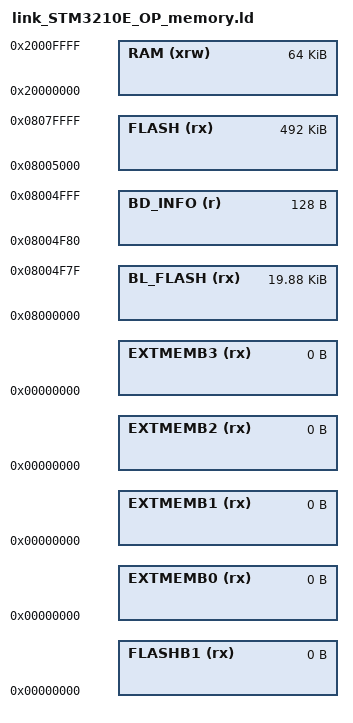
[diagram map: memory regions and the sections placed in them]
MEMORY
{
  RAM (xrw)     : ORIGIN = 0x20000000,        LENGTH = 0x10000
  BL_FLASH (rx) : ORIGIN = 0x08000000,        LENGTH = 0x05000 - 0x00080
  BD_INFO (r)   : ORIGIN = 0x08005000 - 0x80, LENGTH =           0x00080
  FLASH (rx)    : ORIGIN = 0x08005000,        LENGTH = 0x80000 - 0x05000
  FLASHB1 (rx)  : ORIGIN = 0x00000000,        LENGTH = 0
  EXTMEMB0 (rx) : ORIGIN = 0x00000000,        LENGTH = 0
  EXTMEMB1 (rx) : ORIGIN = 0x00000000,        LENGTH = 0
  EXTMEMB2 (rx) : ORIGIN = 0x00000000,        LENGTH = 0
  EXTMEMB3 (rx) : ORIGIN = 0x00000000,        LENGTH = 0
}
